# R7FA6M3AH register map
Vendor: Renesas; Series: RA6; File version: 1.2
CPU: CM4 r0p1, little endian, MPU, FPU, VTOR, 4 interrupt priority bits
Registers are 32-bit, read-write, reset 0x0 unless marked. A register's access mark holds for its fields unless they carry their own. Offsets are from the block's base; [hi:lo] are bit positions; lines under a group give offsets from that group; {n}, {i} and the like mark numbered series; 'fields as' and 'values as' point back to an identical list.

## ADC121 — 12bit A/D Converter 1
Base 0x4005C200
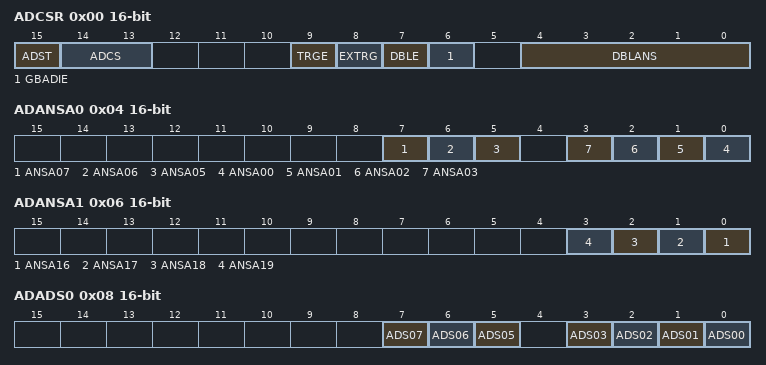
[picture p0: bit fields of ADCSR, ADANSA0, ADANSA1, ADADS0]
0x00 ADCSR 16-bit — A/D Control Register
  [15] ADST read-modifies — A/D Conversion Start
  [14:13] ADCS — Scan Mode Select
  [9] TRGE — Trigger Start Enable
  [8] EXTRG — Trigger Select
  [7] DBLE — Double Trigger Mode Select
  [6] GBADIE — Group B Scan End Interrupt Enable
  [4:0] DBLANS — Double Trigger Channel SelectThese bits select one analog input channel for double triggered operation. The setting is only effective while double trigger mode is selected.
0x04 ADANSA0 16-bit — A/D Channel Select Register A0
  [7] ANSA07 — AN107 Select
  [6] ANSA06 — AN106 Select
  [5] ANSA05 — AN105 Select
  [n] ANSA{n:02} (n=0..3) — AN{n+100} Select
0x06 ADANSA1 16-bit — A/D Channel Select Register A1
  [n-16] ANSA{n} (n=16..19) — AN{n+100} Select
0x08 ADADS0 16-bit — A/D,Converted Value Addition/Average Channel Select Register 0
  [7] ADS07 — A/D,Converted Value Addition/Average Channel AN107 Select
  [6] ADS06 — A/D,Converted Value Addition/Average Channel AN106 Select
  [5] ADS05 — A/D,Converted Value Addition/Average Channel AN105 Select
  [n] ADS{n:02} (n=0..3) — A/D,Converted Value Addition/Average Channel AN{n+100} Select
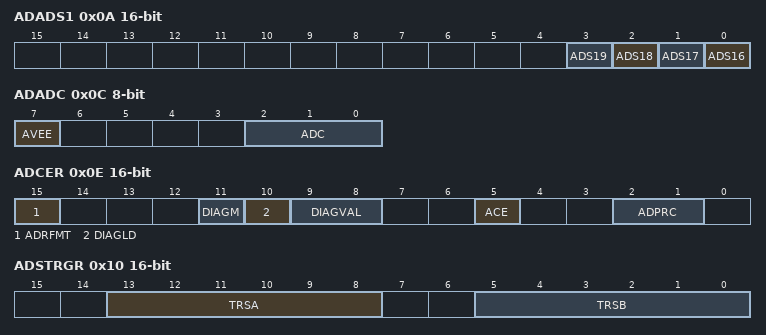
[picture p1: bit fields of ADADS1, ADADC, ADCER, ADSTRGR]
0x0A ADADS1 16-bit — A/D,Converted Value Addition/Average Channel Select Register 1
  [n-16] ADS{n} (n=16..19) — A/D,Converted Value Addition/Average Channel AN{n+100} Select
0x0C ADADC 8-bit — A/D,Converted Value Addition/Average Count Select Register
  [7] AVEE — Average mode enable bit.Note: The AVEE bit converts twice, and only when converting it four times, is effective. Please do not set (ADADC.AVEE=1) to conversion (ADADC.ADC 2:0=010b) three times when you select the average mode.
  [2:0] ADC — Addition frequency selection bit.NOTE: AVEE bit is valid at the only setting of ADC[2:0] bits = 001b or 011b. When average mode is selected by setting the ADADC.AVEE bit to 1, do not set the addition count to three times (ADADC.ADC[2:0] = 010b)
0x0E ADCER 16-bit — A/D Control Extended Register
  [15] ADRFMT — A/D Data Register Format Select
  [11] DIAGM — Self,Diagnosis Enable
  [10] DIAGLD — Self,Diagnosis Mode Select
  [9:8] DIAGVAL — Self,Diagnosis Conversion Voltage Select
  [5] ACE — A/D Data Register Automatic Clearing Enable
  [2:1] ADPRC — A/D Conversion Accuracy Specify
0x10 ADSTRGR 16-bit — A/D Conversion Start Trigger Select Register
  [13:8] TRSA — A/D Conversion Start Trigger SelectSelect the A/D conversion start trigger in single scan mode and continuous mode. In group scan mode, the A/D conversion start trigger for group A is selected.
  [5:0] TRSB — A/D Conversion Start Trigger Select for Group BSelect the A/D conversion start trigger for group B in group scan mode.
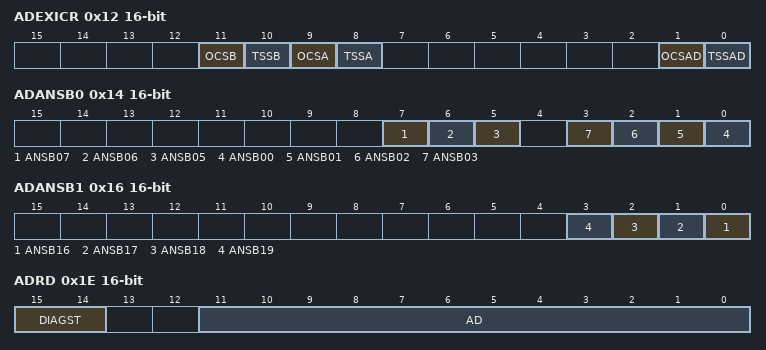
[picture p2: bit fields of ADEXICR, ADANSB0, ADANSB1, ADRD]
0x12 ADEXICR 16-bit — A/D Conversion Extended Input Control Register
  [11] OCSB — Internal Reference Voltage A/D Conversion Select for Group B
  [10] TSSB — Temperature Sensor Output A/D Conversion Select for Group B
  [9] OCSA — Internal Reference Voltage A/D Conversion Select
  [8] TSSA — Temperature Sensor Output A/D Conversion Select
  [1] OCSAD — Internal Reference Voltage A/D converted Value Addition/Average Mode Select
  [0] TSSAD — Temperature Sensor Output A/D converted Value Addition/Average Mode Select
0x14 ADANSB0 16-bit — A/D Channel Select Register B0
  [7] ANSB07 — AN107 Select
  [6] ANSB06 — AN106 Select
  [5] ANSB05 — AN105 Select
  [n] ANSB{n:02} (n=0..3) — AN{n+100} Select
0x16 ADANSB1 16-bit — A/D Channel Select Register B1
  [n-16] ANSB{n} (n=16..19) — AN{n+100} Select
0x18 ADDBLDR 16-bit ro — A/D Data Duplication Register
  [15:0] ADDBLDR — This is a 16-bit read,only register for storing the result of A/D conversion in response to the second trigger in double trigger mode.
0x1A ADTSDR 16-bit ro — A/D Temperature Sensor Data Register
  [15:0] ADTSDR — This is a 16-bit read,only register for storing the A/D conversion result of temperature sensor output.
0x1C ADOCDR 16-bit ro — A/D Internal Reference Voltage Data Register
  [15:0] ADOCDR — This is a 16-bit read,only register for storing the A/D result of internal reference voltage.
0x1E ADRD 16-bit ro — A/D Self,Diagnosis Data Register
  [15:14] DIAGST — Self,Diagnosis Status
  [11:0] AD — A/D,converted value (right,justified)NOTE: Unused bits in the AD bit field are fixed "0"
{0x20+2i} ADDR{i} (i=0..3) 16-bit ro — A/D Data Register {i}
  [15:0] ADDR — The ADDR register is a 16-bit read,only registers for storing the result of A/D conversion.
{0x20+2i} ADDR{i}_1 (i=5..7) 16-bit ro — A/D Data Register {i}
  fields as ADDR0
{0x20+2i} ADDR{i}_2 (i=16..19) 16-bit ro — A/D Data Register {i}
  fields as ADDR0
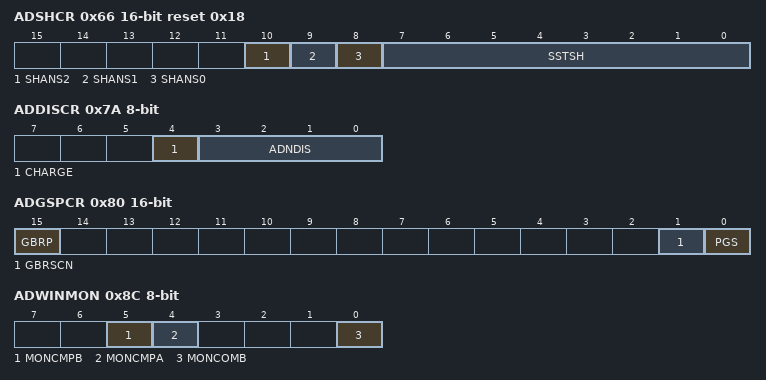
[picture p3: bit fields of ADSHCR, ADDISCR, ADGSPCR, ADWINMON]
0x66 ADSHCR 16-bit reset 0x18 — A/D Sample and Hold Circuit Control Register
  [10] SHANS2 — AN102 sample,and,hold circuit Select
  [9] SHANS1 — AN101 sample,and,hold circuit Select
  [8] SHANS0 — AN100 sample,and,hold circuit Select
  [7:0] SSTSH range 0x04..0xFF — Channel,Dedicated Sample,and,Hold Circuit Sampling Time Setting Set the sampling time (4 to 255 states)
0x7A ADDISCR 8-bit — A/D Disconnection Detection Control Register
  [4] CHARGE — Selection of Precharge or Discharge
  [3:0] ADNDIS — The charging time
0x7C ADSHMSR 8-bit — A/D Sample and Hold Operation Mode Select Register
  [0] SHMD — Channel,Dedicated Sample,and,Hold Circuit Operation Mode Select
0x80 ADGSPCR 16-bit — A/D Group Scan Priority Control Register
  [15] GBRP — Group B Single Scan Continuous Start(Enabled only when PGS = 1. Reserved when PGS = 0.)Note: When the GBRP bit has been set to 1, single scan is performed continuously for group B regardless of the setting of the GBRSCN bit.
  [1] GBRSCN — Group B Restart Setting(Enabled only when PGS = 1. Reserved when PGS = 0.)
  [0] PGS — Group A priority control setting bit.Note: When the PGS bit is to be set to 1, the ADCSR.ADCS[1:0] bits must be set to 01b (group scan mode). If the bits are set to any other values, proper operation is not guaranteed.
0x84 ADDBLDRA 16-bit ro — A/D Data Duplication Register A
  [15:0] ADDBLDRA — This register is a 16-bit read,only registers for storing the result of A/D conversion in response to the respective triggers during extended operation in double trigger mode.
0x86 ADDBLDRB 16-bit ro — A/D Data Duplication Register B
  [15:0] ADDBLDRB — This register is a 16-bit read,only registers for storing the result of A/D conversion in response to the respective triggers during extended operation in double trigger mode.
0x8C ADWINMON 8-bit ro — A/D Compare Function Window A/B Status Monitor Register
  [5] MONCMPB — Comparison Result Monitor B
  [4] MONCMPA — Comparison Result Monitor A
  [0] MONCOMB — Combination result monitorThis bit indicates the combination result.This bit is valid when both window A operation and window B operation are enabled.
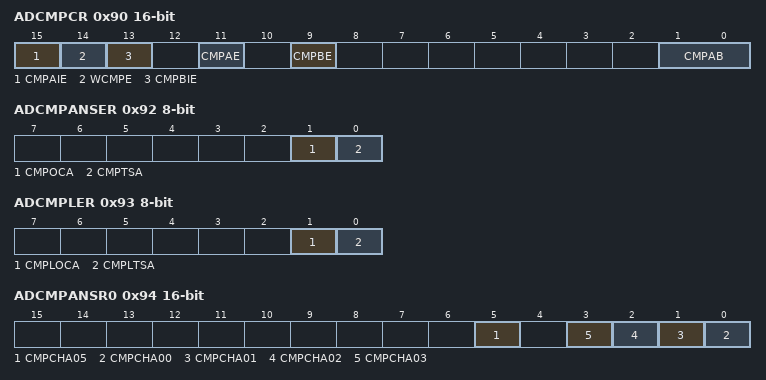
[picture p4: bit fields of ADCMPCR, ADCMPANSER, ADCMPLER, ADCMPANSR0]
0x90 ADCMPCR 16-bit — A/D Compare Function Control Register
  [15] CMPAIE — Compare A Interrupt Enable
  [14] WCMPE — Window Function Setting
  [13] CMPBIE — Compare B Interrupt Enable
  [11] CMPAE — Compare Window A Operation Enable
  [9] CMPBE — Compare Window B Operation Enable
  [1:0] CMPAB — Window A/B Composite Conditions SettingNOTE: These bits are valid when both window A and window B are enabled (CMPAE = 1 and CMPBE = 1).
0x92 ADCMPANSER 8-bit — A/D Compare Function Window A Extended Input Select Register
  [1] CMPOCA — Internal reference voltage Compare selection bit.
  [0] CMPTSA — Temperature sensor output Compare selection bit.
0x93 ADCMPLER 8-bit — A/D Compare Function Window A Extended Input Comparison Condition Setting Register
  [1] CMPLOCA — Compare Window A Internal Reference Voltage ComparisonCondition Select
  [0] CMPLTSA — Compare Window A Temperature Sensor Output Comparison Condition Select
0x94 ADCMPANSR0 16-bit — A/D Compare Function Window A Channel Select Register 0
  [5] CMPCHA05 — Compare Window A Channel AN105 Select
  [n] CMPCHA{n:02} (n=0..3) — Compare Window A Channel AN{n+100} Select
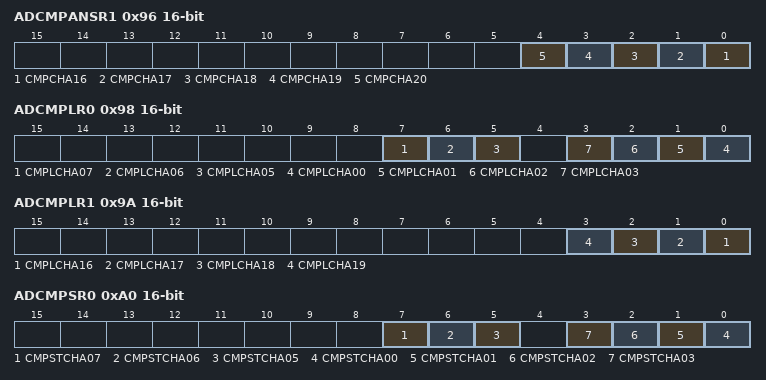
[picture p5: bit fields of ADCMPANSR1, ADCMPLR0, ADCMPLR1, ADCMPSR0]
0x96 ADCMPANSR1 16-bit — A/D Compare Function Window A Channel Select Register 1
  [n-16] CMPCHA{n} (n=16..20) — AN{n+100} Select
0x98 ADCMPLR0 16-bit — A/D Compare Function Window A Comparison Condition Setting Register 0
  [7] CMPLCHA07 — Comparison condition of AN107
  [6] CMPLCHA06 — Comparison condition of AN106
  [5] CMPLCHA05 — Comparison condition of AN105
  [n] CMPLCHA{n:02} (n=0..3) — Comparison condition of AN{n+100}
0x9A ADCMPLR1 16-bit — A/D Compare Function Window A Comparison Condition Setting Register 1
  [n-16] CMPLCHA{n} (n=16..19) — Comparison condition of AN{n+100}
0x9C ADCMPDR0 16-bit — A/D Compare Function Window A Lower,Side Level Setting Register
  [15:0] ADCMPDR0 — The ADCMPDR0 register sets the reference data when the compare window A function is used. ADCMPDR0 sets the lower,side level of window A.
0x9E ADCMPDR1 16-bit — A/D Compare Function Window A Upper,Side Level Setting Register
  [15:0] ADCMPDR1 — The ADCMPDR1 register sets the reference data when the compare window A function is used. ADCMPDR1 sets the upper,side level of window A..
0xA0 ADCMPSR0 16-bit — A/D Compare Function Window A Channel Status Register 0
  [7] CMPSTCHA07 write-0-clears read-modifies — Compare window A flag of AN007
  [6] CMPSTCHA06 write-0-clears read-modifies — Compare window A flag of AN006
  [5] CMPSTCHA05 write-0-clears read-modifies — Compare window A flag of AN005
  [n] CMPSTCHA{n:02} write-0-clears read-modifies (n=0..3) — Compare window A flag of AN{n:03}
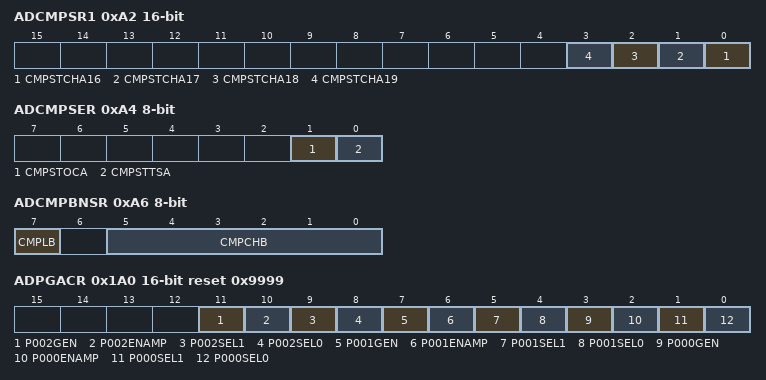
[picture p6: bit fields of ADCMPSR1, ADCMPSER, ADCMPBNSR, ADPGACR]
0xA2 ADCMPSR1 16-bit — A/D Compare Function Window A Channel Status Register 1
  [n-16] CMPSTCHA{n} write-0-clears read-modifies (n=16..19) — Compare window A flag of AN{n:03}
0xA4 ADCMPSER 8-bit — A/D Compare Function Window A Extended Input Channel Status Register
  [1] CMPSTOCA write-0-clears read-modifies — Compare Window A Internal Reference Voltage Compare Flag When window A operation is enabled (ADCMPCR.CMPAE = 1b), this bit indicates the temperature sensor output comparison result. When window A operation is disabled (ADCMPCR.CMPAE = 0b), comparison conditions for CMPSTTSA are not met any time.
  [0] CMPSTTSA write-0-clears read-modifies — Compare Window A Temperature Sensor Output Compare Flag When window A operation is enabled (ADCMPCR.CMPAE = 1b), this bit indicates the temperature sensor output comparison result. When window A operation is disabled (ADCMPCR.CMPAE = 0b), comparison conditions for CMPSTTSA are not met any time.
0xA6 ADCMPBNSR 8-bit — A/D Compare Function Window B Channel Selection Register
  [7] CMPLB — Compare window B Compare condition setting bit.
  [5:0] CMPCHB — Compare window B channel selection bit.The channel that compares it on the condition of compare window B is selected.
0xA8 ADWINLLB 16-bit — A/D Compare Function Window B Lower,Side Level Setting Register
  [15:0] ADWINLLB — This register is used to compare A window function is used to set the lower level of the window B.
0xAA ADWINULB 16-bit — A/D Compare Function Window B Upper,Side Level Setting Register
  [15:0] ADWINULB — This register is used to compare A window function is used to set the higher level of the window B.
0xAC ADCMPBSR 8-bit — A/D Compare Function Window B Status Register
  [0] CMPSTB write-0-clears read-modifies — Compare window B flag.It is a status flag that shows the comparative result of CH (AN100-AN103, AN105-AN107, AN116-AN119, temperature sensor, and internal reference voltage) made the object of window B relation condition.
0xDD ADSSTRL 8-bit reset 0xB — A/D Sampling State Register L
  [7:0] SST range 0x05..0xFF — Sampling Time Setting (AN116-AN119)
0xDE ADSSTRT 8-bit reset 0xB — A/D Sampling State Register T
  [7:0] SST range 0x05..0xFF — Sampling Time Setting (temperature sensor output)
0xDF ADSSTRO 8-bit reset 0xB — A/D Sampling State Register O
  [7:0] SST range 0x05..0xFF — Sampling Time Setting (Internal reference voltage)
{0xE0+i} ADSSTR0{i} (i=0..3) 8-bit reset 0xB — A/D Sampling State Register {i} (Corresponding Channel is AN10{i} )
  [7:0] SST range 0x05..0xFF — Sampling time setting
{0xE0+i} ADSSTR0{i}_1 (i=5..7) 8-bit reset 0xB — A/D Sampling State Register {i} (Corresponding Channel is AN10{i} )
  [7:0] SST range 0x05..0xFF — Sampling time setting
0x1A0 ADPGACR 16-bit reset 0x9999 — A/D Programmable Gain Amplifier Control Register
  [11] P002GEN — PGA P002 gain setting and enable bit
  [10] P002ENAMP — Amplifier enable bit for PGA P002
  [9] P002SEL1 — The amplifier passing is enable for PGA P002
  [8] P002SEL0 — A through amplifier is enable for PGA P002
  [7] P001GEN — PGA P001 gain setting and enable bit
  [6] P001ENAMP — Amplifier enable bit for PGA P001
  [5] P001SEL1 — The amplifier passing is enable for PGA P001
  [4] P001SEL0 — A through amplifier is enable for PGA P001
  [3] P000GEN — PGA P000 gain setting and enable bit
  [2] P000ENAMP — Amplifier enable bit for PGA P000
  [1] P000SEL1 — The amplifier passing is enable for PGA P000
  [0] P000SEL0 — A through amplifier is enable for PGA P000
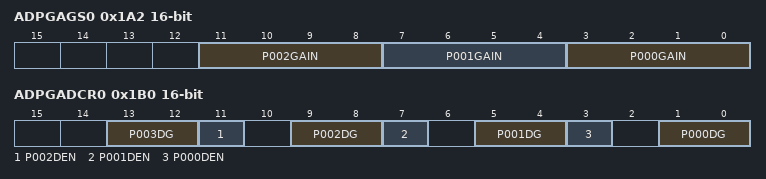
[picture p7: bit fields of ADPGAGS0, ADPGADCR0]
0x1A2 ADPGAGS0 16-bit — A/D Programmable Gain Amplifier Gain Setting Register 0
  [11:8] P002GAIN — PGA P002 gain setting bit.The gain magnification of (ADPGSDCR0.P002GEN=0b) when the shingle end is input and each PGA P002 is set. When the differential motion is input, (ADPGSDCR0.P002GEN=1b) sets the gain magnification when the differential motion is input by the combination with ADPGSDCR0.P002DG 1:0.
  [7:4] P001GAIN — PGA P001 gain setting bit.The gain magnification of (ADPGSDCR0.P001GEN=0b) when the shingle end is input and each PGA P001 is set. When the differential motion is input, (ADPGSDCR0.P001GEN=1b) sets the gain magnification when the differential motion is input by the combination with ADPGSDCR0.P001DG 1:0.
  [3:0] P000GAIN — PGA P000 gain setting bit.The gain magnification of (ADPGSDCR0.P000GEN=0b) when the shingle end is input and each PGA P000 is set. When the differential motion is input, (ADPGSDCR0.P000GEN=1b) sets the gain magnification when the differential motion is input by the combination with ADPGSDCR0.P000DG 1:0.
0x1B0 ADPGADCR0 16-bit — A/D Programmable Gain Amplifier Differential Input Control Register
  [13:12] P003DG — P003 Differential Input Gain SettingNOTE: When these bits are used, set {P003DEN, P003GEN} to 11b.
  [11] P002DEN — P002 Differential Input Enable
  [9:8] P002DG — P002 Differential Input Gain SettingNOTE: When these bits are used, set {P002DEN, P002GEN} to 11b.
  [7] P001DEN — P001 Differential Input Enable
  [5:4] P001DG — P001 Differential Input Gain SettingNOTE: When these bits are used, set {P001DEN, P001GEN} to 11b.
  [3] P000DEN — P000 Differential Input Enable
  [1:0] P000DG — P000 Differential Input Gain SettingNOTE: When these bits are used, set {P000DEN, P000GEN} to 11b.
